VERSION ""

NS_ :

BS_:

BU_: DSC

VAL_TABLE_ DSC_CC_ID 357 "MDM activated." 354 "Start-off assistance inactive!" 353 "Brakes overheated!" 352 "Brakes too hot!" 336 "Yellow TPMS light." 334 "EOL Standardize RPA." 237 "DSC Failure" 236 "ABS and DSC failure." 215 "Yellow DSC light." 184 "DTC activated," 74 "Brake fluid low!" 71 "Replace Brake pads!" 63 "Tyre failure!" 50 "Flat tyre monitor failed." 42 "EBV/CBC failure." 36 "DSC deactivated!" 35 "DSC failed." 24 "DBC failure." ;
VAL_TABLE_ ST_DSC_CC_MSG 1 "TURN DSC CC MSG ON" 0 "TURN DSC CC MSG OFF" ;
VAL_TABLE_ HABR 2 "ON" 1 "OFF" ;
VAL_TABLE_ ST_MOD_DKG 15 "INVALID" 13 "TCT_ES" 12 "TQ_DEC" 6 "N_REGULATION" 4 "TCT_INTV_INC" 3 "TCT_INTV_DEC" 2 "Creep" 0 "No Intervention" ;
VAL_TABLE_ ST_BRP 3 "Signal Invalid" 2 "No Statement Possible" 1 "Brake Pressure Present" 0 "No Brake Pressure" ;
VAL_TABLE_ ST_WHL_TOL 2 "SIGNAL INVALID" 1 "ADJUSTMENT DONE" 0 "ADJUSTMENT NOT DONE" ;
VAL_TABLE_ ST_EDC_MODE 3 "Sport +" 1 "Sport" 0 "Comfort" ;
VAL_TABLE_ MFUNC_LWK 16384 "Description for the value '0x1F00'" 4096 "Recirculate" 256 "Voice Command" 32 "Down" 22 "Up" 8 "Volume -" 4 "Volume +" 1 "Telephone" 0 "No Button Pressed" ;
VAL_TABLE_ INTERIOR_LIGHTS 9 "INTERIOR & EXTERIOR LIGHTS ON" 8 "INTERIOR LIGHTS ON" ;
VAL_TABLE_ ST_HEADLIGHTS 7 "Description for the value '0x6'" 5 "DIP BEAM" 4 "PARK" ;
VAL_TABLE_ vtST_VEH_DVCO 7 "signal invalid" 3 "vehicle moves, direction n/a" 2 "moves backward, FL/FR backward" 1 "moves forward, FL/FR forward" 0 "vehicle standing" ;
VAL_TABLE_ vtOP_PUBU_CCTR_ACC 127 "signal invalid" 64 "tap axial, resume" 16 "tap up / down, Off" 8 "overpress backward, lower step" 4 "tap backwards, set / retard" 2 "overpress forward, higher step" 1 "tap forward, set / accelerate" 0 "nothing to do" ;
VAL_TABLE_ vtST_LDST_GEN 3 "signal invalid" 2 "Utilization rate = 100%" 1 "50% <= Utilization rate < 100%" 0 "0% <= Utilization rate < 50%" ;
VAL_TABLE_ vtST_GEN 3 "signal invalid" 2 "defective" 1 "in igh-temperature cutoff" 0 "OK" ;
VAL_TABLE_ vtST_KL 2 "signal invalid" 1 "terminal on" 0 "temrinal off" ;
VAL_TABLE_ vtST_RCPT_ENG_X 2 "timeout error" 1 "plausibility/activity error" 0 "status ok" ;
VAL_TABLE_ vtST_TORQ_AVL 15 "signal invalid" 3 "intervention ign & inj not exec." 2 "intervention inj not executed" 1 "intervention ign not executed" 0 "intervention request executed" ;
VAL_TABLE_ vtST_CTCTR_V 11 "pedal kickdown" 10 "pedal transgress" 9 "pedal pressed" 8 "pedal not pressed" 7 "cc regulation, speed up" 6 "cc regulation, recall" 5 "cc regulation, constant" 4 "cc regulation, retard" 1 "acc regulation, ped pressed" 0 "acc regulation, ped not pressed" ;
VAL_TABLE_ vtST_CCLT 3 "signal invalid" 2 "closed" 1 "controlled" 0 "disengaged" ;
VAL_TABLE_ vtST_GR_GRB 15 "signal invalid" 10 "6. gear" 9 "5. gear" 8 "4. gear" 7 "3. gear" 6 "2. gear" 5 "1. gear" 4 "reserved" 3 "P" 2 "R" 1 "N" 0 "reserved" ;
VAL_TABLE_ vtST_WALI_ENG 3 "signal invalid" 1 "yellow" 0 "off" ;
VAL_TABLE_ vtST_INTF_CCTRA_KL 4 "error in fgr" 2 "error in acc module" 1 "error in kombi" 0 "okay" ;
VAL_TABLE_ vtST_UN_V_SPDM 3 "signal invalid" 1 "mph" 0 "km/h" ;
VAL_TABLE_ vtST_ACC_MOD_DME 7 "signal invalid" 6 "reserved" 5 "driver has stepped over" 4 "brake active" 3 "reserved" 2 "normal" 1 "stand by" 0 "passive" ;
VAL_TABLE_ vtST_ACC_SWO_SYS_DME 3 "signal invalid" 2 "system okay" 1 "system shutdown, error detected" 0 "reserved" ;
VAL_TABLE_ vtST_CLCTR 0 "no regulation" 255 "signal invalid" 16 "msr regulation" 8 "hba regulation" 4 "dsc regulation" 2 "asc regulation" 1 "abs regulation" ;
VAL_TABLE_ vtST_DCRN_AVL 15 "signal invalid" 2 "requirement EMF accepted" 0 "no requirement" ;
VAL_TABLE_ vtST_DSC 7 "signal invalid" 6 "under voltage" 5 "reserved" 4 "traction mode" 3 "reserved" 2 "faulty" 1 "passive" 0 "all clear" ;
VAL_TABLE_ vtRPM_IDLG_SPEC 3 "signal invalid" 1 "increased idle rpm required" 0 "no requirement on idle rpm" ;
VAL_TABLE_ vtSTWA 32769 "right stop" 32767 "left stop" 0 "straight-ahead position" ;
VAL_TABLE_ vtOBD_ERR 3 "signal invalid" 1 "OBD-relevant error occurred" 0 "no OBD-relevant error present" ;
VAL_TABLE_ vtST_OTMP_GRB 3 "signal invalid" 2 "cooling stage 2" 1 "cooling stage 1" 0 "no requirement" ;
VAL_TABLE_ vtST_SWO_KL_30 3 "signal invalid" 2 "shutdown by the PM done" 1 "no shutdown by the PM done" 0 "reserved" ;
VAL_TABLE_ vtST_BTSW 3 "signal invalid" 1 "battery main switch opens in 5s" 0 "battery main switch closed" ;
VAL_TABLE_ vtCTR_SLCK 3 "signal invalid" 2 "requirement Shiftlock" 1 "no requirement Shiftlock" 0 "not allowed" ;
VAL_TABLE_ vtST_SW_WAUP 3 "signal invalid" 2 "EGS forced switching active" 1 "engine warm" 0 "warming up" ;
VAL_TABLE_ vtST_ENG_RUN 3 "signal invalid" 2 "engine running" 1 "engine starting" 0 "engine off" ;
VAL_TABLE_ vtST_IDLG_ENG 3 "signal invalid" 1 "not idling" 0 "idling" ;
VAL_TABLE_ vtRPM_ENG_ERR 3 "signal invalid" 1 "speed sensor defective" 0 "signal RPM_ENG correct" ;
VAL_TABLE_ vtST_INFS 1 "thrust cutoff active" 0 "no action" ;
VAL_TABLE_ vtST_SW_LEV_RPM 1 "idle speed < the threshold value" 0 "idle speed > the threshold value" ;
VAL_TABLE_ vtST_TORQ_TAR 3 "invalid signal" 2 "decrease torque" 1 "increase torque" 0 "no actual torque request" ;
VAL_TABLE_ DOOR_FLAP_STA 1 "Opened" 0 "Closed" ;
VAL_TABLE_ BOOT_BONNET_STATUS 4 "Bonnet opened" 1 "Boot opened" ;
VAL_TABLE_ DR_STATUS 64 "RR door opened" 16 "RL door opened" 4 "FR door opened" 1 "FL door opened" ;
VAL_TABLE_ GEAR_SELECTION 29699 "D" 27136 "Idle" 22786 "Change to N, down" 18177 "Change to N, up" 11524 "R" 80 "P" ;

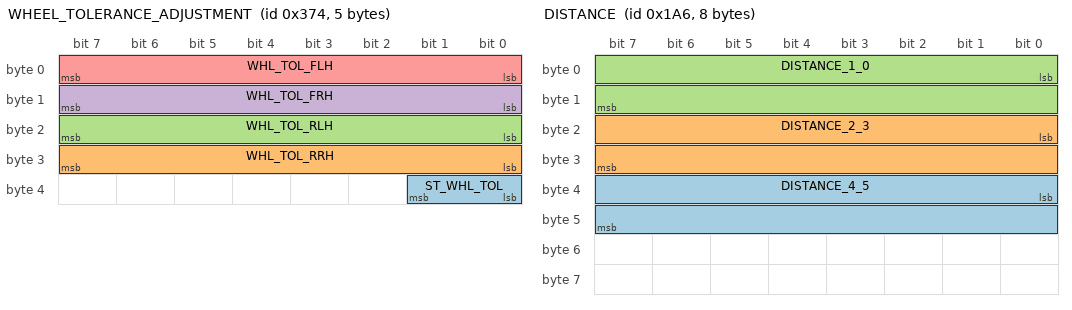
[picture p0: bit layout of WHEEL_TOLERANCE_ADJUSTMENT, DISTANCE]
BO_ 884 WHEEL_TOLERANCE_ADJUSTMENT: 5 DSC
 SG_ ST_WHL_TOL : 32|2@1+ (1,0) [0|0] "" Vector__XXX
 SG_ WHL_TOL_RRH : 24|8@1- (0.1,0) [0|0] "%" Vector__XXX
 SG_ WHL_TOL_RLH : 16|8@1- (0.1,0) [-12.8|12.7] "%" Vector__XXX
 SG_ WHL_TOL_FRH : 8|8@1- (0.1,0) [0|0] "%" Vector__XXX
 SG_ WHL_TOL_FLH : 0|8@1- (0.1,1) [-11.8|13.7] "%" Vector__XXX

BO_ 422 DISTANCE: 8 DSC
 SG_ DISTANCE_4_5 : 32|16@1+ (1,0) [0|0] "" Vector__XXX
 SG_ DISTANCE_2_3 : 16|16@1+ (1,0) [0|0] "" Vector__XXX
 SG_ DISTANCE_1_0 : 0|16@1+ (1,0) [0|0] "" Vector__XXX

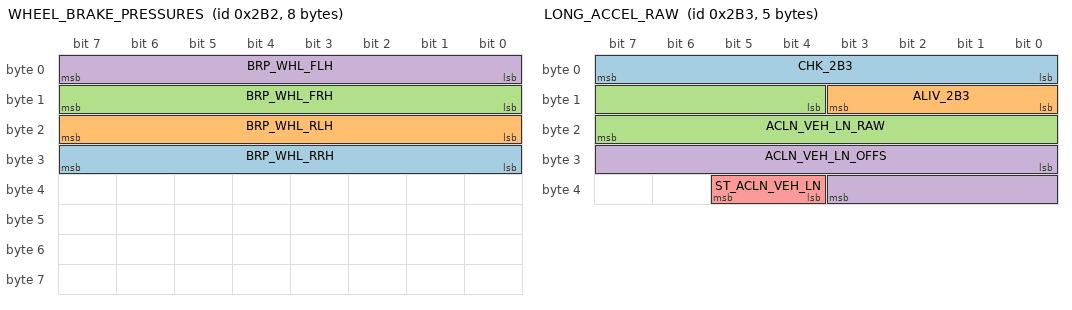
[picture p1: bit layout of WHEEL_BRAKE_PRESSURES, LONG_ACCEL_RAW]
BO_ 690 WHEEL_BRAKE_PRESSURES: 8 DSC
 SG_ BRP_WHL_RRH : 24|8@1+ (1,0) [0|0] "bar" Vector__XXX
 SG_ BRP_WHL_RLH : 16|8@1+ (1,0) [0|0] "bar" Vector__XXX
 SG_ BRP_WHL_FRH : 8|8@1+ (1,0) [0|0] "bar" Vector__XXX
 SG_ BRP_WHL_FLH : 0|8@1+ (1,0) [0|0] "bar" Vector__XXX

BO_ 691 LONG_ACCEL_RAW: 5 DSC
 SG_ CHK_2B3 : 0|8@1+ (1,0) [0|255] "" Vector__XXX
 SG_ ALIV_2B3 : 8|4@1+ (1,0) [0|14] "" Vector__XXX
 SG_ ACLN_VEH_LN_RAW : 12|12@1+ (0.025,-51.2) [-51.2|51.15] "m/s2" Vector__XXX
 SG_ ACLN_VEH_LN_OFFS : 24|12@1+ (0.025,-51.2) [-2.35|2.35] "m/s2" Vector__XXX
 SG_ ST_ACLN_VEH_LN : 36|2@1+ (1,0) [0|3] "" Vector__XXX

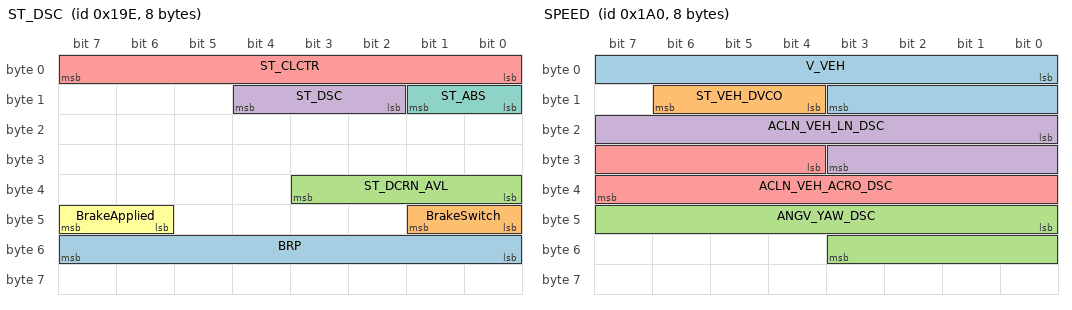
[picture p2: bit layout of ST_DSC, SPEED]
BO_ 414 ST_DSC: 8 DSC
 SG_ BRP : 48|8@1+ (1,0) [0|0] "bar" Vector__XXX
 SG_ BrakeSwitch : 40|2@1+ (1,0) [0|0] "" Vector__XXX
 SG_ ST_DCRN_AVL : 32|4@1+ (1,0) [0|0] "" Vector__XXX
 SG_ ST_DSC : 10|3@1+ (1,0) [0|0] "" Vector__XXX
 SG_ ST_CLCTR : 0|8@1+ (1,0) [0|0] "" Vector__XXX
 SG_ BrakeApplied : 46|2@1+ (1,0) [0|0] "" Vector__XXX
 SG_ ST_ABS : 8|2@1+ (1,0) [0|0] "" Vector__XXX

BO_ 416 SPEED: 8 DSC
 SG_ V_VEH : 0|12@1+ (0.1,0) [0.1|350] "km/h"  DSC
 SG_ ST_VEH_DVCO : 12|3@1+ (1,0) [0|0] "" Vector__XXX
 SG_ ANGV_YAW_DSC : 40|12@1- (0.05,0) [0|0] "deg/s" Vector__XXX
 SG_ ACLN_VEH_LN_DSC : 16|12@1- (0.025,0) [-51.175|51.175] "m/s2" Vector__XXX
 SG_ ACLN_VEH_ACRO_DSC : 28|12@1- (0.025,0) [-51.175|51.175] "m/s2"  DSC

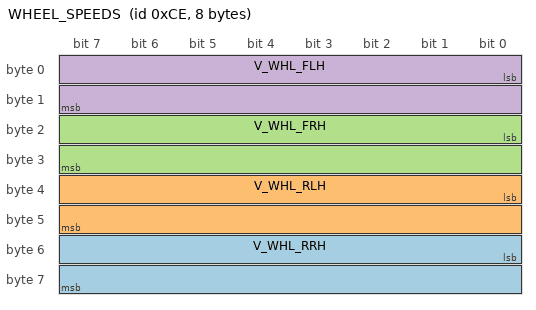
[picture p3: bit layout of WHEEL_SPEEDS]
BO_ 206 WHEEL_SPEEDS: 8 DSC
 SG_ V_WHL_RRH : 48|16@1- (0.0625,0) [-300|300] "km/h" Vector__XXX
 SG_ V_WHL_RLH : 32|16@1- (0.0625,0) [-300|300] "km/h" Vector__XXX
 SG_ V_WHL_FRH : 16|16@1- (0.0625,0) [-300|300] "km/h" Vector__XXX
 SG_ V_WHL_FLH : 0|16@1- (0.0625,0) [-300|300] "km/h" Vector__XXX

CM_ SG_ 884 WHL_TOL_FLH "% = (100% + WHL_TOL_FLH)";
CM_ BO_ 691 "Raw longitudinal accelerometer (F-CAN sensor cluster 0x0D1 bytes 4-5) plus its learned zero offset. 50 ms. Handlers 0x7B7F4/0x7B83C/0x7B8B6/0x7B8E2/0x7D7D8. Bits 4.6-4.7 unused (always 1).";
CM_ SG_ 691 CHK_2B3 "checksum, can_tx_checksum8 0x7D24C: S = sum(payload) + CAN id, out = low8(S + S>>8)";
CM_ SG_ 691 ALIV_2B3 "alive counter 0..14 (0x40471D low nibble)";
CM_ SG_ 691 ACLN_VEH_LN_RAW "measured longitudinal specific force from the accelerometer: 0x404A00 unfiltered, NO offset correction, includes road gradient. Firmware: raw*201/512 + 2048, clamp 0..4094. 1 mg/LSB source assumed (same as the lateral channel), so 1 bit = 0.02498 m/s2. Not the same as ACLN_VEH_LN_DSC on 0x1A0 (front-wheel derived).";
CM_ SG_ 691 ACLN_VEH_LN_OFFS "learned accelerometer zero offset 0x4049FD (s8, 2 mg/LSB, clamp +/-119 = +/-0.238 g; DSC uses offset*20 at 0x404A04). Firmware: offs*201/256 + 2048. Same scale as ACLN_VEH_LN_RAW: corrected ax = ACLN_VEH_LN_RAW - ACLN_VEH_LN_OFFS.";
CM_ SG_ 691 ST_ACLN_VEH_LN "status of the raw ax signal (ax_signal_get(3) out[3]): 2 when b5 or b6 (invalid) is set, else 0. Value 1 needs b2 clear, which this path never produces.";
CM_ SG_ 414 BRP "Brake Pressure";
CM_ SG_ 414 BrakeSwitch "State brake pressure
";
CM_ SG_ 414 ST_DCRN_AVL "status deceleration actual-value:";
CM_ SG_ 416 V_VEH "vehicle speed, average of front wheel speeds";
CM_ SG_ 416 ANGV_YAW_DSC "yaw rate from yaw sensor";
CM_ SG_ 416 ACLN_VEH_LN_DSC "longitudinal accel from front wheels, NOT yaw sensor";
CM_ SG_ 416 ACLN_VEH_ACRO_DSC "lateral accel from yaw sensor";
VAL_ 884 ST_WHL_TOL 2 "SIGNAL INVALID" 1 "ADJUSTMENT DONE" 0 "ADJUSTMENT NOT DONE" ;
VAL_ 691 ACLN_VEH_LN_RAW 4095 "signal invalid" ;
VAL_ 691 ACLN_VEH_LN_OFFS 4095 "signal invalid" ;
VAL_ 691 ST_ACLN_VEH_LN 0 "valid" 1 "not used" 2 "invalid" ;
VAL_ 414 BrakeSwitch 0 "Off" 1 "On" 2 "SwitchFault" 3 "Invalid" ;
VAL_ 414 ST_DCRN_AVL 3 "HBA Intervention" 1 "DCC Intervention" 15 "signal invalid" 2 "EMF Intervention" 0 "no requirement" ;
VAL_ 414 ST_DSC 0 "DSC OK" 1 "DSC Off" 2 "DSC Fault" 3 "Steer Angle Invalid" 4 "DTC / M Mode" 5 "ABS FAULT" 6 "Startup / Sensor system problem" 7 "SIGNAL INVALID" ;
VAL_ 414 ST_CLCTR 64 "DYNO_ACTIVE" 32 "EBV_REGULATION" 0 "no regulation" 255 "signal invalid" 16 "msr regulation" 8 "hba regulation" 4 "DSC/TCS regulation" 2 "ASR regulation" 1 "abs regulation" ;
VAL_ 414 BrakeApplied 0 "NotBraking" 1 "Braking" 2 "SwitchInvalid" 3 "SwitchAndPressureInvalid" ;
VAL_ 414 ST_ABS 0 "Normal" 1 "Fallback level" 2 "Malfunction" 3 "Invalid signal" ;
VAL_ 416 ST_VEH_DVCO 0 "vehicle standing" 1 "moves forward, FL/FR forward" 2 "moves backward, FL/FR backward" 3 "moving, direction unknown" 7 "signal invalid" ;
